# STM32F101xG register map
File version: 1.0
Registers are 32-bit, read-write, reset 0x0 unless marked. A register's access mark holds for its fields unless they carry their own. Offsets are from the block's base; [hi:lo] are bit positions.

## RTC — Real-Time Clock
Base 0x40002800
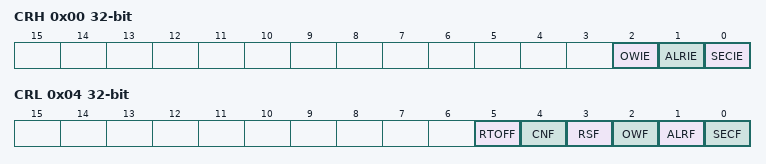
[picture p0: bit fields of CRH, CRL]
0x00 CRH
  [2] OWIE — OverfloW Interrupt Enable
  [1] ALRIE — Alarm Interrupt Enable
  [0] SECIE — Second Interrupt Enable
0x04 CRL
  [5] RTOFF — RTC operation OFF
  [4] CNF — Configuration Flag
  [3] RSF — Registers Synchronized Flag
  [2] OWF — OverfloW Flag
  [1] ALRF — Alarm Flag
  [0] SECF — Second Flag
0x08 PRLH
  [3:0] PRL — RTC Prescaler Reload Value High
0x0C PRLL
  [15:0] PRL — RTC Prescaler Reload Value Low
0x10 DIVH
  [3:0] RTC_DIV — RTC Clock Divider High
0x14 DIVL
  [15:0] RTC_DIV — RTC Clock Divider Low
0x18 CNTH
  [15:0] RTC_CNT — RTC Counter High
0x1C CNTL
  [15:0] RTC_CNT — RTC Counter Low
0x20 ALRH
  [15:0] RTC_ALR — RTC Alarm High
0x24 ALRL
  [15:0] RTC_ALR — RTC Alarm Low

## WWDG — Window WATCHDOG
Base 0x40002C00
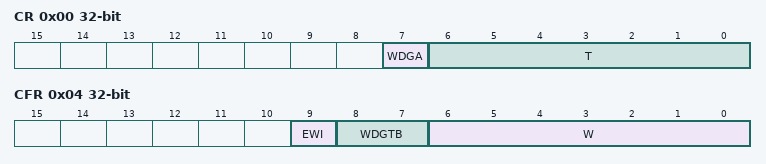
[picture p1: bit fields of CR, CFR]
0x00 CR — WWDG Control register
  [7] WDGA — Activation bit
  [6:0] T — T[6:0] bits (7-Bit counter (MSB to LSB))
0x04 CFR — WWDG Configuration register
  [9] EWI — Early Wakeup Interrupt
  [8:7] WDGTB — WDGTB[1:0] bits (Timer Base)
    0=PRESCALER_1 (WWDG counter clock = (PCLK1/4096)/1); 1=PRESCALER_2 (WWDG counter clock = (PCLK1/4096)/2); 2=PRESCALER_4 (WWDG counter clock = (PCLK1/4096)/4); 3=PRESCALER_8 (WWDG counter clock = (PCLK1/4096)/8)
  [6:0] W — W[6:0] bits (7-bit window value)
0x08 SR — WWDG Status register
  [0] EWIF — Early Wakeup Interrupt Flag

## IWDG — Independent WATCHDOG
Base 0x40003000
0x00 KR — Key register
  [15:0] KEY — Key value (write only, read 0000h)
0x04 PR — Prescaler register
  [2:0] PR — PR[2:0] (Prescaler divider)
0x08 RLR — Reload register
  [11:0] RL — Watchdog counter reload value
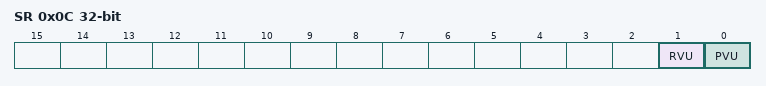
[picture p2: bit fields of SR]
0x0C SR — Status register
  [1] RVU — Watchdog counter reload value update
  [0] PVU — Watchdog prescaler value update

## SPI2 — Serial Peripheral Interface
Base 0x40003800
Same registers: SPI3 0x40003C00, SPI1 0x40013000
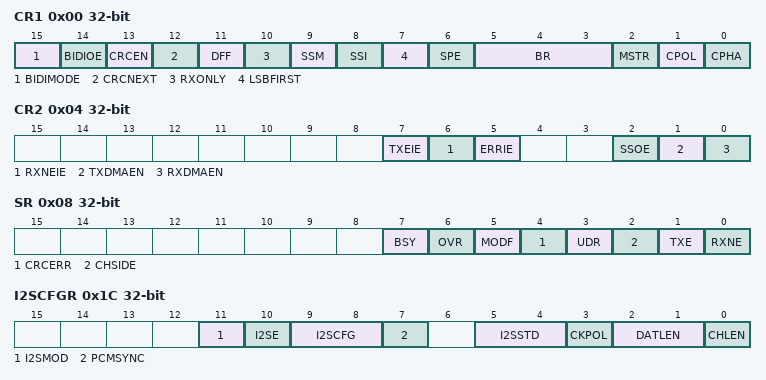
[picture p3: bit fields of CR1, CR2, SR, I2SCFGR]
0x00 CR1
  [15] BIDIMODE — Bidirectional data mode enable
  [14] BIDIOE — Output enable in bidirectional mode
  [13] CRCEN — Hardware CRC calculation enable
  [12] CRCNEXT — Transmit CRC next
  [11] DFF — Data Frame Format
    0=DATAWIDTH_8BIT (Data length for SPI transfer: 8 bits); 1=DATAWIDTH_16BIT (Data length for SPI transfer: 16 bits)
  [10] RXONLY — Receive only
  [9] SSM — Software slave management
  [8] SSI — Internal slave select
  [7] LSBFIRST — Frame Format
    1=LSB_FIRST (Data is transmitted/received with the LSB first); 0=MSB_FIRST (Data is transmitted/received with the MSB first)
  [6] SPE — SPI Enable
  [5:3] BR — BR[2:0] bits (Baud Rate Control)
    0=DIV2 (BaudRate control equal to fPCLK/2); 1=DIV4 (BaudRate control equal to fPCLK/4); 2=DIV8 (BaudRate control equal to fPCLK/8); 3=DIV16 (BaudRate control equal to fPCLK/16); 4=DIV32 (BaudRate control equal to fPCLK/32); 5=DIV64 (BaudRate control equal to fPCLK/64); 6=DIV128 (BaudRate control equal to fPCLK/128); 7=DIV256 (BaudRate control equal to fPCLK/256)
  [2] MSTR — Master Selection
  [1] CPOL — Clock Polarity
    0=LOW (Clock to 0 when idle); 1=HIGH (Clock to 1 when idle)
  [0] CPHA — Clock Phase
    0=PHASE_1EDGE (First clock transition is the first data capture edge); 1=PHASE_2EDGE (Second clock transition is the first data capture edge)
0x04 CR2
  [7] TXEIE — Tx buffer Empty Interrupt Enable
  [6] RXNEIE — RX buffer Not Empty Interrupt Enable
  [5] ERRIE — Error Interrupt Enable
  [2] SSOE — SS Output Enable
  [1] TXDMAEN — Tx Buffer DMA Enable
  [0] RXDMAEN — Rx Buffer DMA Enable
0x08 SR
  [7] BSY — Busy flag
  [6] OVR — Overrun flag
  [5] MODF — Mode fault
  [4] CRCERR — CRC Error flag
  [3] UDR — Underrun flag
  [2] CHSIDE — Channel side
  [1] TXE — Transmit buffer Empty
  [0] RXNE — Receive buffer Not Empty
0x0C DR
  [15:0] DR — Data Register
0x10 CRCPR
  [15:0] CRCPOLY — CRC polynomial register
0x14 RXCRCR
  [15:0] RXCRC
0x18 TXCRCR
  [15:0] TXCRC
0x1C I2SCFGR
  [11] I2SMOD — I2S mode selection
  [10] I2SE — I2S Enable
  [9:8] I2SCFG — I2SCFG[1:0] bits (I2S configuration mode)
    0=SLAVE_TX (Slave Tx configuration); 1=SLAVE_RX (Slave Rx configuration); 2=MASTER_TX (Master Tx configuration); 3=MASTER_RX (Master Rx configuration)
  [7] PCMSYNC — PCM frame synchronization
  [5:4] I2SSTD — I2SSTD[1:0] bits (I2S standard selection)
  [3] CKPOL — steady state clock polarity
    0=LOW (Clock steady state is low level); 1=HIGH (Clock steady state is high level)
  [2:1] DATLEN — DATLEN[1:0] bits (Data length to be transferred)
  [0] CHLEN — Channel length (number of bits per audio channel)
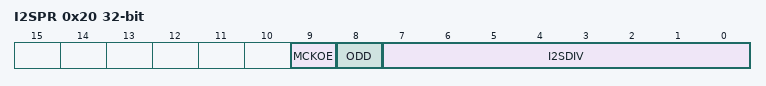
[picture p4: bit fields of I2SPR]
0x20 I2SPR
  [9] MCKOE — Master Clock Output Enable
  [8] ODD — Odd factor for the prescaler
  [7:0] I2SDIV — I2S Linear prescaler
